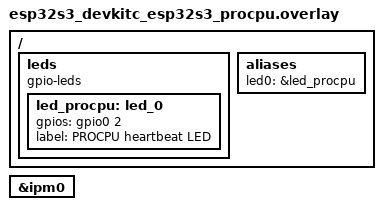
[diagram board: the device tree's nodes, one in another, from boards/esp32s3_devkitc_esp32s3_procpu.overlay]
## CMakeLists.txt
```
cmake_minimum_required(VERSION 3.20.0)

find_package(Zephyr REQUIRED HINTS $ENV{ZEPHYR_BASE})
project(01_hello_dualcore_procpu)

target_sources(app PRIVATE src/main.c)
```

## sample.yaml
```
sample:
  name: 01 Hello Dual-Core (AMP procpu + appcpu, no IPC yet)
  description: >
    Minimal ESP32-S3 AMP scaffold - builds and flashes two independent
    Zephyr images (procpu + appcpu) with west sysbuild. Each core blinks
    its own LED at a different rate to prove both are running
    independently; no inter-processor communication yet (see Lab 02).
common:
  sysbuild: true
tests:
  sample.boards.espressif.esp32s3_devkitc.hello_dualcore:
    build_only: true
    platform_allow: esp32s3_devkitc/esp32s3/procpu
    tags:
      - ipc
      - amp
      - esp32s3
```

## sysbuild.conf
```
# sysbuild.conf - sysbuild's OWN Kconfig namespace (SB_CONFIG_*), not the
# app's prj.conf.
#
# Espressif boards default to building MCUboot alongside the app whenever
# --sysbuild is used. This lab has nothing to do with OTA/firmware
# upgrades - it's a plain two-image AMP build (procpu + appcpu) - so
# MCUboot is unwanted overhead here.
#
# SB_CONFIG_BOOTLOADER is a Kconfig *choice* (single-select), and
# Espressif's board-level Kconfig.sysbuild defaults it to
# BOOTLOADER_MCUBOOT. Explicitly selecting BOOTLOADER_NONE=y is what
# actually turns MCUboot off.
SB_CONFIG_BOOTLOADER_NONE=y
SB_CONFIG_BOOTLOADER_MCUBOOT=n
```

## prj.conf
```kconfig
# 01_HELLO_DUALCORE_LAB - core0 (procpu) image
#
# This core has full UART console support, so it proves itself alive two
# ways: a blinking LED (same signal core1 has to rely on exclusively) and
# a logged heartbeat message over the console UART.

CONFIG_GPIO=y

CONFIG_LOG=y
CONFIG_LOG_MODE_IMMEDIATE=y

# Required even though this lab has no IPC of its own: on this board,
# appcpu is never released from reset unless &ipm0 is enabled on BOTH
# images (confirmed on real hardware - see the troubleshooting doc for
# how this was found). Not used to send/receive anything here.
CONFIG_IPM=y
CONFIG_ESP32_SOFT_IPM=y
```

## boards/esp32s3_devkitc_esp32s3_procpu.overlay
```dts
/*
 * Overlay for 01_HELLO_DUALCORE_LAB - core0 (procpu) image
 *
 * This lab uses no communication peripheral at all (no I2C/SPI) - the only
 * job of this core is to prove it is running, independently of core1.
 * A plain GPIO-driven LED (Zephyr's standard "gpio-leds" pattern, exposed
 * as the `led0` alias) is used for that, plus the console UART for
 * printk/LOG output.
 *
 * GPIO2 is a plain, unused GPIO on this board (not a strapping pin
 * 0/3/45/46, not a USB-JTAG pin 19/20) - chosen freely for this lab and
 * intended as this IPC track's convention for the procpu heartbeat LED
 * in later labs too.
 */

#include <zephyr/dt-bindings/gpio/gpio.h>

/ {
	leds {
		compatible = "gpio-leds";
		led_procpu: led_0 {
			gpios = <&gpio0 2 GPIO_ACTIVE_HIGH>;
			label = "PROCPU heartbeat LED";
		};
	};

	aliases {
		led0 = &led_procpu;
	};
};

/*
 * Required even though this lab has no IPC of its own: on this board,
 * appcpu is never released from reset unless &ipm0 is enabled on BOTH
 * images (confirmed on real hardware - see the troubleshooting doc for
 * how this was found). Not used to send/receive anything here - Lab 02
 * is where this project starts actually using inter-core communication.
 */
&ipm0 {
	status = "okay";
};
```

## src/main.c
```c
/*
 * main.c - 01_HELLO_DUALCORE_LAB (core0 / procpu image)
 *
 * Purpose of this lab: nothing more than proving that two independent
 * Zephyr images can run on ESP32-S3's two cores at the same time, built
 * and flashed together with a single `west build --sysbuild` /
 * `west flash`. There is NO inter-processor communication in this lab -
 * that starts in Lab 02. This core and remote/src/main.c (core1) never
 * talk to each other; they just happen to blink at different rates so
 * it's visually obvious on the breadboard that both are alive and that
 * neither is waiting on the other.
 *
 * core0 (procpu) has full UART console support, so it proves itself
 * alive two ways: this LED, and a logged heartbeat line every 500ms.
 * Compare this with core1, which has only the LED - see the appcpu
 * main.c and the doc for why.
 */

#include <zephyr/kernel.h>
#include <zephyr/drivers/gpio.h>
#include <zephyr/logging/log.h>

LOG_MODULE_REGISTER(app_procpu, LOG_LEVEL_INF);

static const struct gpio_dt_spec led = GPIO_DT_SPEC_GET(DT_ALIAS(led0), gpios);

#define BLINK_PERIOD_MS 500

int main(void)
{
	LOG_INF("01_HELLO_DUALCORE_LAB (core0/procpu) starting");

	if (!gpio_is_ready_dt(&led)) {
		LOG_ERR("LED device not ready - check overlay/wiring");
		return -1;
	}

	int ret = gpio_pin_configure_dt(&led, GPIO_OUTPUT_INACTIVE);

	if (ret) {
		LOG_ERR("gpio_pin_configure_dt failed: %d", ret);
		return -1;
	}

	bool led_state = false;

	while (1) {
		led_state = !led_state;
		gpio_pin_set_dt(&led, led_state);
		LOG_INF("procpu heartbeat - LED %s", led_state ? "ON" : "OFF");
		k_msleep(BLINK_PERIOD_MS);
	}

	return 0;
}
```
